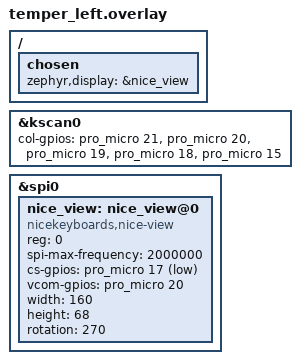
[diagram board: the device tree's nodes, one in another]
/*
 * Copyright (c) 2020 Pete Johanson
 *
 * SPDX-License-Identifier: MIT
 */

#include "temper.dtsi"

/ {
    chosen {
        zephyr,display = &nice_view;
    };
};

&kscan0 {
    col-gpios
        = <&pro_micro 21 GPIO_ACTIVE_HIGH>
        , <&pro_micro 20 GPIO_ACTIVE_HIGH>
        , <&pro_micro 19 GPIO_ACTIVE_HIGH>
        , <&pro_micro 18 GPIO_ACTIVE_HIGH>
        , <&pro_micro 15 GPIO_ACTIVE_HIGH>
        ;
};

&spi0 {
    status = "okay"; /* This line enables the SPI bus */

    nice_view: nice_view@0 {
        compatible = "nicekeyboards,nice-view";
        reg = <0>;
        status = "okay"; /* This line enables the display */
        spi-max-frequency = <2000000>;
        cs-gpios = <&pro_micro 17 GPIO_ACTIVE_LOW>;
        vcom-gpios = <&pro_micro 20 GPIO_ACTIVE_HIGH>;
        width = <160>;
        height = <68>;
        rotation = <270>;
    };
};
